VERSION ""

NS_ :

BS_:

BU_: Group3 Test_Node

BO_ 1216 Grp3_Sensor: 8 Group3
 SG_ Temperature : 0|32@1+ (0.1,-55) [-40|85] "C" Vector__XXX
 SG_ Humidity : 32|32@1+ (0.1,0) [0|100] "%" Vector__XXX

BO_ 1217 Grp3_GPS_Pos: 8 Group3
 SG_ Latitude : 0|32@1- (0.000001,0) [-90|90] "deg" Vector__XXX
 SG_ Longitude : 32|32@1- (0.000001,0) [-180|180] "deg" Vector__XXX

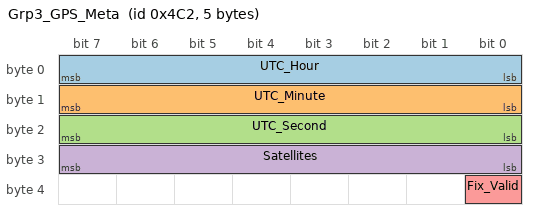
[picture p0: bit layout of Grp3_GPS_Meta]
BO_ 1218 Grp3_GPS_Meta: 5 Group3
 SG_ UTC_Hour : 0|8@1+ (1,0) [0|23] "h" Vector__XXX
 SG_ UTC_Minute : 8|8@1+ (1,0) [0|59] "min" Vector__XXX
 SG_ UTC_Second : 16|8@1+ (1,0) [0|59] "s" Vector__XXX
 SG_ Satellites : 24|8@1+ (1,0) [0|12] "" Vector__XXX
 SG_ Fix_Valid : 32|1@1+ (1,0) [0|1] "" Vector__XXX
